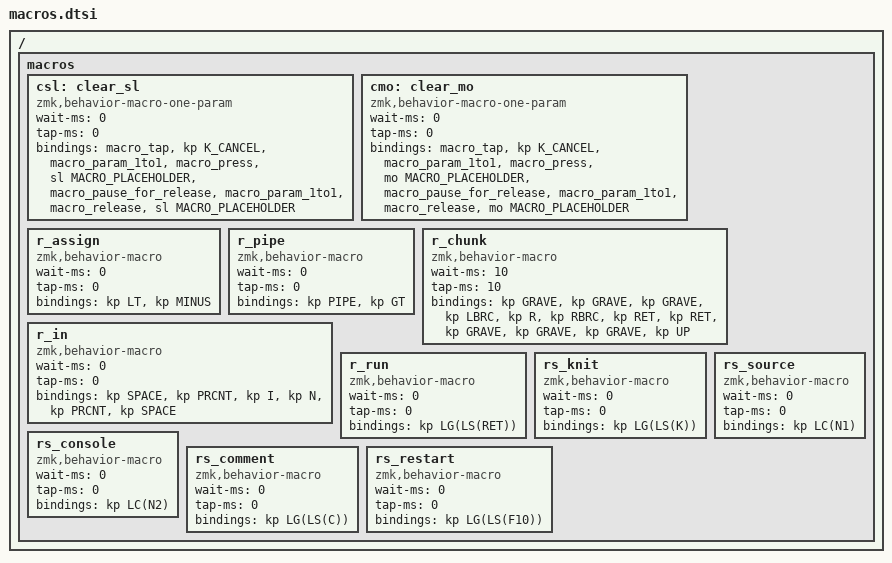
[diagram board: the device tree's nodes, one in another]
/ {
  macros {
    /*
      Practically identical to &sl, except it triggers a `K_CANCEL` right before to clear
      any active smart layers. This prevents nested/stacked layer activation when needed.

      Params:
        1. Layer to switch to

      Example:
        `&csl L1`
     */
    /omit-if-no-ref/ csl: clear_sl {
      wait-ms = <0>;
      tap-ms = <0>;
      compatible = "zmk,behavior-macro-one-param";
      #binding-cells = <1>;
      bindings = <&macro_tap &kp K_CANCEL>,
        <&macro_param_1to1>,
        <&macro_press &sl MACRO_PLACEHOLDER>,
        <&macro_pause_for_release>,
        <&macro_param_1to1>,
        <&macro_release &sl MACRO_PLACEHOLDER>;
    };

    /*
      Practically identical to &mo, except it triggers a `K_CANCEL` right before to clear
      any active smart layers. This prevents nested/stacked layer activation when needed.
      It's also useful to maintain more consistent expectations when holding a cancel/exit layer
      key from a smart layer.

      Params:
        1. Layer to switch to

      Example:
        `&cmo L1`
     */
    /omit-if-no-ref/ cmo: clear_mo {
      wait-ms = <0>;
      tap-ms = <0>;
      compatible = "zmk,behavior-macro-one-param";
      #binding-cells = <1>;
      bindings = <&macro_tap &kp K_CANCEL>,
        <&macro_param_1to1>,
        <&macro_press &mo MACRO_PLACEHOLDER>,
        <&macro_pause_for_release>,
        <&macro_param_1to1>,
        <&macro_release &mo MACRO_PLACEHOLDER>;
    };

    /*
      R assignment operator: <-
      Outputs: < followed by -
     */
    /omit-if-no-ref/ r_assign: r_assign {
      wait-ms = <0>;
      tap-ms = <0>;
      compatible = "zmk,behavior-macro";
      #binding-cells = <0>;
      bindings = <&kp LT &kp MINUS>;
    };

    /*
      R pipe operator: |>
      Outputs: | followed by >
     */
    /omit-if-no-ref/ r_pipe: r_pipe {
      wait-ms = <0>;
      tap-ms = <0>;
      compatible = "zmk,behavior-macro";
      #binding-cells = <0>;
      bindings = <&kp PIPE &kp GT>;
    };

    /*
      RMarkdown/Quarto code chunk insertion
      Outputs: ```{r}
               [cursor here]
               ```
     */
    /omit-if-no-ref/ r_chunk: r_chunk {
      wait-ms = <10>;
      tap-ms = <10>;
      compatible = "zmk,behavior-macro";
      #binding-cells = <0>;
      bindings = <&kp GRAVE &kp GRAVE &kp GRAVE &kp LBRC &kp R &kp RBRC>
               , <&kp RET &kp RET>
               , <&kp GRAVE &kp GRAVE &kp GRAVE>
               , <&kp UP>;
    };

    /*
      R %in% operator
      Outputs: ` %in% ` (with spaces)
     */
    /omit-if-no-ref/ r_in: r_in {
      wait-ms = <0>;
      tap-ms = <0>;
      compatible = "zmk,behavior-macro";
      #binding-cells = <0>;
      bindings = <&kp SPACE &kp PRCNT &kp I &kp N &kp PRCNT &kp SPACE>;
    };

    /*
      Run current line/selection (VS Code / RStudio)
      Outputs: Cmd+Shift+Enter
     */
    /omit-if-no-ref/ r_run: r_run {
      wait-ms = <0>;
      tap-ms = <0>;
      compatible = "zmk,behavior-macro";
      #binding-cells = <0>;
      bindings = <&kp LG(LS(RET))>;
    };

    /*
      RStudio: Knit document
      Outputs: Cmd+Shift+K
     */
    /omit-if-no-ref/ rs_knit: rs_knit {
      wait-ms = <0>;
      tap-ms = <0>;
      compatible = "zmk,behavior-macro";
      #binding-cells = <0>;
      bindings = <&kp LG(LS(K))>;
    };

    /*
      RStudio: Focus Source pane
      Outputs: Ctrl+1
     */
    /omit-if-no-ref/ rs_source: rs_source {
      wait-ms = <0>;
      tap-ms = <0>;
      compatible = "zmk,behavior-macro";
      #binding-cells = <0>;
      bindings = <&kp LC(N1)>;
    };

    /*
      RStudio: Focus Console pane
      Outputs: Ctrl+2
     */
    /omit-if-no-ref/ rs_console: rs_console {
      wait-ms = <0>;
      tap-ms = <0>;
      compatible = "zmk,behavior-macro";
      #binding-cells = <0>;
      bindings = <&kp LC(N2)>;
    };

    /*
      RStudio: Comment/uncomment selection
      Outputs: Cmd+Shift+C
     */
    /omit-if-no-ref/ rs_comment: rs_comment {
      wait-ms = <0>;
      tap-ms = <0>;
      compatible = "zmk,behavior-macro";
      #binding-cells = <0>;
      bindings = <&kp LG(LS(C))>;
    };

    /*
      RStudio: Restart R session
      Outputs: Cmd+Shift+F10
     */
    /omit-if-no-ref/ rs_restart: rs_restart {
      wait-ms = <0>;
      tap-ms = <0>;
      compatible = "zmk,behavior-macro";
      #binding-cells = <0>;
      bindings = <&kp LG(LS(F10))>;
    };
  };
};
